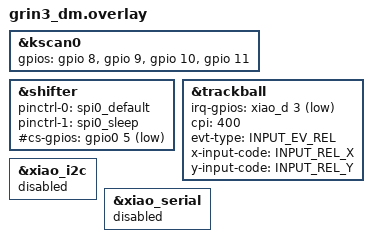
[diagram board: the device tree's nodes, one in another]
#include "grin3.dtsi"
 
&kscan0 {
    gpios
        = <&gpio 8 (GPIO_ACTIVE_HIGH)>
        , <&gpio 9 (GPIO_ACTIVE_HIGH)>
        , <&gpio 10 (GPIO_ACTIVE_HIGH)>
        , <&gpio 11 (GPIO_ACTIVE_HIGH)>
        ;
};

&shifter {
    status = "okay";
    pinctrl-0 = <&spi0_default>;
    pinctrl-1 = <&spi0_sleep>;
    pinctrl-names = "default", "sleep";
    #cs-gpios = <&gpio0 5 GPIO_ACTIVE_LOW>;
};

&trackball {
    status = "okay";
	irq-gpios = <&xiao_d 3 (GPIO_ACTIVE_LOW | GPIO_PULL_UP)>;
	cpi = <400>;
	evt-type = <INPUT_EV_REL>;
	x-input-code = <INPUT_REL_X>;
	y-input-code = <INPUT_REL_Y>;
};

&xiao_i2c { status = "disabled"; };
&xiao_serial { status = "disabled"; };
